AUTOSAR XML (schema 00047)
package /AUTOSAR/DiagnosticManagement/CompositionSwComponentTypes_Blueprint
  composition sw component type DM
    component DM1: type=DM1
package /AUTOSAR/DiagnosticManagement/AdaptiveApplicationSwComponentTypes_Blueprint
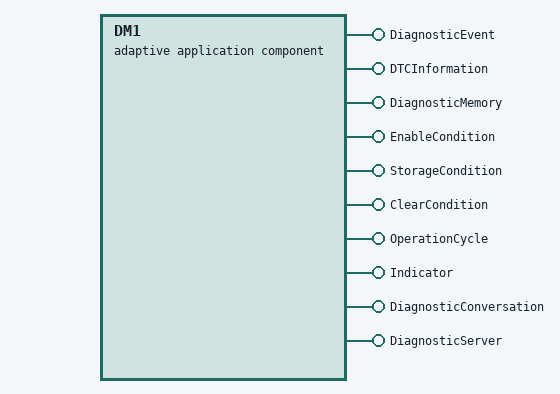
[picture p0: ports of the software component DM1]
  adaptive application sw component type DM1
    10 x provide port:
      DiagnosticEvent: variation-point=formal-blueprint-generator=expression=FOR SoftwareCluster : MODEL.filterType("SoftwareCluster"); DiagnosticEvent : MODEL.filterType("DiagnosticEvent"); WHERE DiagnosticEvent.isWithin(SoftwareCluster);, provided-interface=DiagnosticEvent  # Provides information on diagnostic event.
      DTCInformation: variation-point=formal-blueprint-generator=expression=FOR SoftwareCluster : MODEL.filterType("SoftwareCluster"); DiagnosticMemoryDestination : MODEL.filterType("DiagnosticMemoryDestination"); WHERE DiagnosticMemoryDestination.isWithin(SoftwareCluster);, provided-interface=DTCInformation  # Provides information on diagnostic event.
      DiagnosticMemory: variation-point=formal-blueprint-generator=expression=FOR SoftwareCluster : MODEL.filterType("SoftwareCluster"); DiagnosticMemoryDestination : MODEL.filterType("DiagnosticMemoryDestination"); WHERE DiagnosticMemoryDestination.isWithin(SoftwareCluster);, provided-interface=DiagnosticMemory  # Provides access to the fault memories.
      EnableCondition: variation-point=formal-blueprint-generator=expression=FOR SoftwareCluster : MODEL.filterType("SoftwareCluster"); DiagnosticEnableCondition : MODEL.filterType("DiagnosticEnableCondition"); WHERE DiagnosticEnableCondition.isWithin(SoftwareCluster);, provided-interface=EnableCondition  # Provides functionality for handling of enable conditions.
      StorageCondition: variation-point=formal-blueprint-generator=expression=FOR SoftwareCluster : MODEL.filterType("SoftwareCluster"); DiagnosticStorageCondition : MODEL.filterType("DiagnosticStorageCondition"); WHERE DiagnosticStorageCondition.isWithin(SoftwareCluster);, provided-interface=StorageCondition  # Provides functionality for handling of storage conditions.
      ClearCondition: variation-point=formal-blueprint-generator=expression=FOR SoftwareCluster : MODEL.filterType("SoftwareCluster"); DiagnosticClearCondition : MODEL.filterType("DiagnosticClearCondition"); WHERE DiagnosticClearCondition.isWithin(SoftwareCluster);, provided-interface=ClearCondition  # Provides functionality for handling of clear conditions.
      OperationCycle: variation-point=formal-blueprint-generator=expression=FOR SoftwareCluster : MODEL.filterType("SoftwareCluster"); DiagnosticOperationCycle : MODEL.filterType("DiagnosticOperationCycle"); WHERE DiagnosticOperationCycle.isWithin(SoftwareCluster);, provided-interface=OperationCycle  # Provides functionality for handling of operation cycles.
      Indicator: variation-point=formal-blueprint-generator=expression=FOR SoftwareCluster : MODEL.filterType("SoftwareCluster"); DiagnosticIndicator : MODEL.filterType("DiagnosticIndicator"); WHERE DiagnosticIndicator.isWithin(SoftwareCluster);, provided-interface=Indicator  # Provides functionality for handling of indicators.
      DiagnosticConversation: variation-point=formal-blueprint-generator=expression=FOR SoftwareCluster : MODEL.filterType("SoftwareCluster"); Number : MODEL.filterType("Number"); WHERE Number.isWithin(SoftwareCluster);, provided-interface=DiagnosticConversation  # Provides information about Diagnostic Conversation.
      DiagnosticServer: variation-point=formal-blueprint-generator=expression=FOR SoftwareCluster : MODEL.filterType("SoftwareCluster");, provided-interface=DiagnosticServer  # Provides information about the ControlDTCStatus
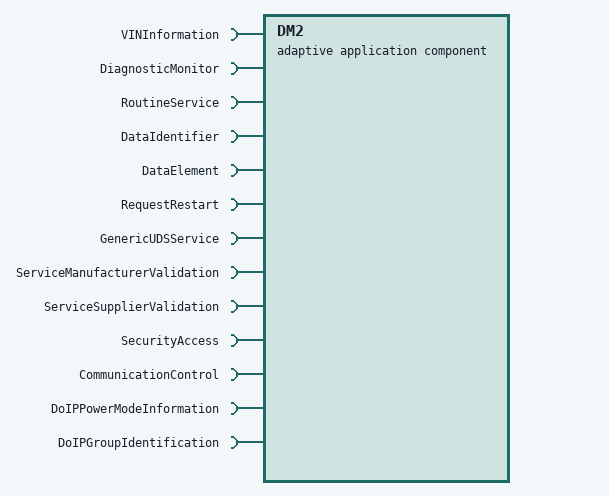
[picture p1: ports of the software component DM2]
  adaptive application sw component type DM2
    13 x require port:
      VINInformation: required-interface=VINInformation  # Requires handler for VIN information.
      DiagnosticMonitor: variation-point=formal-blueprint-generator=expression=FOR SoftwareCluster : MODEL.filterType("SoftwareCluster"); DiagnosticEvent : MODEL.filterType("DiagnosticEvent"); WHERE DiagnosticEvent.isWithin(SoftwareCluster);, required-interface=DiagnosticMonitor  # Requires diagnostic monitor reporting results of diagnostic event monitoring.
      RoutineService: variation-point=formal-blueprint-generator=expression=FOR SoftwareCluster : MODEL.filterType("SoftwareCluster"); DiagnosticRoutine : MODEL.filterType("DiagnosticRoutine"); WHERE DiagnosticRoutine.isWithin(SoftwareCluster);, required-interface=RoutineService  # Requires application providing methods of configured signature.
      DataIdentifier: variation-point=formal-blueprint-generator=expression=FOR SoftwareCluster : MODEL.filterType("SoftwareCluster"); DiagnosticDataIdentifier : MODEL.filterType("DiagnosticDataIdentifier"); WHERE DiagnosticDataIdentifier.isWithin(SoftwareCluster);, required-interface=DataIdentifier  # This is the default service interface for a DiagnosticDataIdentifier.
      DataElement: variation-point=formal-blueprint-generator=expression=FOR SoftwareCluster : MODEL.filterType("SoftwareCluster"); DiagnosticDataElement : MODEL.filterType("DiagnosticDataElement"); WHERE DiagnosticDataElement.isWithin(SoftwareCluster);, required-interface=DataElement  # This is the service interface for any DiagnosticDataElement which is not used within a DataIdentifier service.
      RequestRestart: variation-point=formal-blueprint-generator=expression=FOR SoftwareCluster : MODEL.filterType("SoftwareCluster");, required-interface=RequestRestart  # This is the service interface for requesting a restart of the machine, SWCL or application.
      GenericUDSService: variation-point=formal-blueprint-generator=expression=FOR SoftwareCluster : MODEL.filterType("SoftwareCluster"); DiagnosticServiceSwMapping : MODEL.filterType("DiagnosticServiceSwMapping"); WHERE DiagnosticServiceSwMapping.isWithin(SoftwareCluster);, required-interface=GenericUDSService  # Generic handler for UDS services. Can be mapped to any single diagnostic object (SID, Sub-Function, DID, RID,...).
      ServiceManufacturerValidation: variation-point=formal-blueprint-generator=expression=FOR SoftwareCluster : MODEL.filterType("SoftwareCluster");, required-interface=ServiceManufacturerValidation  # This service is the manufacturer notification handler.
      ServiceSupplierValidation: variation-point=formal-blueprint-generator=expression=FOR SoftwareCluster : MODEL.filterType("SoftwareCluster");, required-interface=ServiceSupplierValidation  # This service is the supplier notification handler.
      SecurityAccess: variation-point=formal-blueprint-generator=expression=FOR SoftwareCluster : MODEL.filterType("SoftwareCluster"); DiagnosticSecurityLevel : MODEL.filterType("DiagnosticSecurityLevel"); WHERE DiagnosticSecurityLevel.isWithin(SoftwareCluster);, required-interface=SecurityAccess  # SecurityAccess.
      CommunicationControl: variation-point=formal-blueprint-generator=expression=FOR SoftwareCluster : MODEL.filterType("SoftwareCluster");, required-interface=CommunicationControl  # CommunicationControl.
      DoIPPowerModeInformation: required-interface=DoIPPowerModeInformation
      DoIPGroupIdentification: required-interface=DoIPGroupIdentification
package /AUTOSAR/DiagnosticManagement/ServiceInterfaces_Blueprint
  23 x service interface, all with is-service=true:
    DiagnosticEvent
      namespaces:
        symbol props ara
        symbol props diag
      field EventStatus: type=EventStatusByteType, has-getter=true, has-notifier=true, has-setter=false  # Contains the current status of the event.
      field WIRStatus: type=WIRStatusType, has-getter=true, has-notifier=true, has-setter=true  # Contains the current WIR status of the event.
      methods:
        operation GetDTCNumber: possible-ap-error-set=Common  # Returns the DTC related to the event.
          arg DTCFormat: type=DTCFormatType, direction=IN, server-argument-impl-policy=USE-ARGUMENT-TYPE  # Define DTC format for the return value.
          arg DTCOfEvent: type=DTCType, direction=OUT, server-argument-impl-policy=USE-ARGUMENT-TYPE  # DTC number in respective DTCFormatType
        operation GetDebouncingStatus  # Gets the debouncing status of an event.
          arg debouncingState: type=DebouncingStateType, direction=OUT, server-argument-impl-policy=USE-ARGUMENT-TYPE  # Current debouncing state
        operation GetFaultDetectionCounter  # Returns the current value of fault detection counter of this event.
          arg faultDetectionCounter: type=FaultDetectionCounterType, direction=OUT, server-argument-impl-policy=USE-ARGUMENT-TYPE  # Current FaultDetectionCounter value
    DiagnosticMonitor
      namespaces:
        symbol props ara
        symbol props diag
      events:
        data MonitorAction: type=MonitorActionType  # Contains either the last (un-)qualified test result of the diagnostic monitor or commands to control the debouncing or to force a prestorage.
      methods:
        operation InitMonitor: fire-and-forget=true  # Event-specific notification for monitors about clearing, operation cycle restart or enable/storage condition re-enabling.
          arg reason: type=InitMonitorReasonType, direction=IN, server-argument-impl-policy=USE-ARGUMENT-TYPE  # The reason for initiallizing the monitor.
    DTCInformation
      namespaces:
        symbol props ara
        symbol props diag
      events:
        data DTCStatusChanged: type=DTCStatusChangedType  # Notification about the change in the status of a DTC.
        data SnapshotRecordUpdated: type=SnapshotRecordUpdatedType  # Notification about an update of a SnapshotRecord.
      methods:
        operation GetCurrentStatus: possible-ap-error-set=Common  # Determines the status of a DTC.
          arg DTC: type=DTCType, direction=IN, server-argument-impl-policy=USE-ARGUMENT-TYPE  # DTC whose status is requested.
          arg UdsDTCStatusByte: type=UdsDTCStatusByteType, direction=OUT, server-argument-impl-policy=USE-ARGUMENT-TYPE  # Contains the status of the DTC.
    DiagnosticMemory
      namespaces:
        symbol props ara
        symbol props diag
      field NumberOfStoredEntries: type=uint32_t, has-getter=true, has-notifier=true, has-setter=false  # Numbner of currently stored fault memory entries.
      methods:
        operation Clear: possible-ap-error-set=ClearFailedReason  # Method for Clearing a DTC or a group of DTCs.
          arg DTC: type=DTCGroupType, direction=IN, server-argument-impl-policy=USE-ARGUMENT-TYPE  # DTC group to be cleared.
    Indicator
      namespaces:
        symbol props ara
        symbol props diag
      field IndicatorStatus: type=IndicatorStatusType, has-getter=true, has-notifier=true, has-setter=false  # Contains the current state of an indicator.
    OperationCycle
      namespaces:
        symbol props ara
        symbol props diag
      field State: type=OperationCycleStateType, has-getter=true, has-notifier=true, has-setter=true  # Contains the current state of an operation cycle.
    StorageCondition
      namespaces:
        symbol props ara
        symbol props diag
      field State: type=StateType, has-getter=true, has-notifier=false, has-setter=true  # Contains the current state of an storage condition.
    EnableCondition
      namespaces:
        symbol props ara
        symbol props diag
      field State: type=StateType, has-getter=true, has-notifier=false, has-setter=true  # Contains the current state of an enable condition.
    ClearCondition
      namespaces:
        symbol props ara
        symbol props diag
      field State: type=StateType, has-getter=true, has-notifier=false, has-setter=true  # Contains the current state of an clear DTC condition.
    DiagnosticConversation
      namespaces:
        symbol props ara
        symbol props diag
      4 x field, all with has-getter=true, has-notifier=true, has-setter=false:
        ActivityStatus: type=ActivityStatusType  # Represents the status of an active conversation.
        DiagnosticSession: type=DiagnosticSessionType  # Represents the current active diagnostic session of an active conversation.
        DiagnosticSecurityLevel: type=DiagnosticSecurityLevelType  # Represents the current active diagnostic security level of an active conversation.
        Identifier: type=DiagnosticConversationIdentifierType  # Contains the identifier (i.e. DiagnosticProtocolKind, TargetAddress, SourceAddress) of the diagnostic conversation.
      methods:
        operation ResetToDefaultSession: fire-and-forget=true  # Method to reset the current session to default session.
    DiagnosticServer
      namespaces:
        symbol props ara
        symbol props diag
      field ControlDTCStatus: type=ControlDtcStatusType, has-getter=true, has-notifier=true, has-setter=false  # Contains the current status of the ControlDTCStatus
      methods:
        operation EnableControlDTC: fire-and-forget=true  # Enforce restoring DTC setting.
    RoutineService: variation-point=formal-blueprint-generator=expression=FOR SoftwareCluster : MODEL.filterType("SoftwareCluster"); DiagnosticRoutine : MODEL.filterType("DiagnosticRoutine"); WHERE DiagnosticRoutine.isWithin(SoftwareCluster);
      namespaces:
        symbol props ara
        symbol props diag
      methods:
        4 x operation:
          Start: possible-ap-error-set=UDSNegativeResponseCodeRegular, variation-point=blueprint-condition=note=p=l-1=Let Method Routine.getAttribute("start").  # Called for sub-function start of a routine.
            arg req_X:  # IN-Parameter of the start sub-function according to DiagnosticRoutine.
              type=custom
              direction=IN
              server-argument-impl-policy=USE-ARGUMENT-TYPE
              variation-point=formal-blueprint-generator={expression=FOR arg : Method.getAttribute("request"); LET DiagnosticDataElement = arg.getAttribute("dataElement"); swDataDefProps = DiagnosticDataElement.getAttribute("swDataDefProps"); BaseTypeRef = swDataDefProps.getAttribute("baseTypeRef");, "DataType according to {DiagnosticDataElement}.swDataDefProps."}
            arg metaInfo: type=MetaInfoType, direction=IN, server-argument-impl-policy=USE-ARGUMENT-TYPE  # MetaInfo of the request.
            arg resp_X:  # OUT-Parameter of the start sub-function according to DiagnosticRoutine.
              type=custom
              direction=OUT
              server-argument-impl-policy=USE-ARGUMENT-TYPE
              variation-point=formal-blueprint-generator={expression=FOR arg : Method.getAttribute("response"); LET DiagnosticDataElement = arg.getAttribute("dataElement"); swDataDefProps = DiagnosticDataElement.getAttribute("swDataDefProps"); BaseTypeRef = swDataDefProps.getAttribute("baseTypeRef");, "DataType according to {DiagnosticDataElement}.swDataDefProps."}
          Stop: possible-ap-error-set=UDSNegativeResponseCodeRegular, variation-point=blueprint-condition=note=p=l-1=Let Method Routine.getAttribute("stop").  # Called for sub-function stop of a routine if configured.
            arg req_X:  # IN-Parameter of the stop sub-function according to DiagnosticRoutine.
              type=custom
              direction=IN
              server-argument-impl-policy=USE-ARGUMENT-TYPE
              variation-point=formal-blueprint-generator={expression=FOR arg : Method.getAttribute("request"); LET DiagnosticDataElement = arg.getAttribute("dataElement"); swDataDefProps = DiagnosticDataElement.getAttribute("swDataDefProps"); BaseTypeRef = swDataDefProps.getAttribute("baseTypeRef");, "DataType according to {DiagnosticDataElement}.swDataDefProps."}
            arg metaInfo: type=MetaInfoType, direction=IN, server-argument-impl-policy=USE-ARGUMENT-TYPE  # MetaInfo of the request.
            arg resp_X:  # OUT-Parameter of the start sub-function according to DiagnosticRoutine.
              type=custom
              direction=OUT
              server-argument-impl-policy=USE-ARGUMENT-TYPE
              variation-point=formal-blueprint-generator={expression=FOR arg : Method.getAttribute("response"); LET DiagnosticDataElement = arg.getAttribute("dataElement"); swDataDefProps = DiagnosticDataElement.getAttribute("swDataDefProps"); BaseTypeRef = swDataDefProps.getAttribute("baseTypeRef");, "DataType according to {DiagnosticDataElement}.swDataDefProps."}
          RequestResults: possible-ap-error-set=UDSNegativeResponseCodeRegular, variation-point=blueprint-condition=note=p=l-1=Let Method Routine.getAttribute("requestResults").  # Called for sub-function requestRoutineResults of a routine if configured.
            arg req_X:  # IN-Parameter of the requestResults sub-function according to DiagnosticRoutine.
              type=custom
              direction=IN
              server-argument-impl-policy=USE-ARGUMENT-TYPE
              variation-point=formal-blueprint-generator={expression=FOR arg : Method.getAttribute("request"); LET DiagnosticDataElement = arg.getAttribute("dataElement"); swDataDefProps = DiagnosticDataElement.getAttribute("swDataDefProps"); BaseTypeRef = swDataDefProps.getAttribute("baseTypeRef");, "DataType according to {DiagnosticDataElement}.swDataDefProps."}
            arg metaInfo: type=MetaInfoType, direction=IN, server-argument-impl-policy=USE-ARGUMENT-TYPE  # MetaInfo of the request.
            arg resp_X:  # OUT-Parameter of the requestRoutineResults sub-function according to DiagnosticRoutine.
              type=custom
              direction=OUT
              server-argument-impl-policy=USE-ARGUMENT-TYPE
              variation-point=formal-blueprint-generator={expression=FOR arg : Method.getAttribute("response"); LET DiagnosticDataElement = arg.getAttribute("dataElement"); swDataDefProps = DiagnosticDataElement.getAttribute("swDataDefProps"); BaseTypeRef = swDataDefProps.getAttribute("baseTypeRef");, "DataType according to {DiagnosticDataElement}.swDataDefProps."}
          Cancel: fire-and-forget=true  # Called if the current conversation is canceled.
            arg metaInfo: type=MetaInfoType, direction=IN, server-argument-impl-policy=USE-ARGUMENT-TYPE, variation-point=blueprint-condition=note=p=l-1=MetaInfoType: Meta-Inf map, which contains key-value pairs according to MetaInfoKeyType.  # MetaInfo of the request.
    DataIdentifier: variation-point=formal-blueprint-generator=expression=FOR SoftwareCluster : MODEL.filterType("SoftwareCluster"); DiagnosticDataIdentifier : MODEL.filterType("DiagnosticDataIdentifier"); WHERE DiagnosticDataIdentifier.isWithin(SoftwareCluster);
      namespaces:
        symbol props ara
        symbol props diag
      methods:
        operation Read: possible-ap-error-set=UDSNegativeResponseCodeRegular  # Called for ReadDataByIdentifer request for this DiagnosticDataIdentifier (if configured).
          arg metaInfo: type=MetaInfoType, direction=IN, server-argument-impl-policy=USE-ARGUMENT-TYPE  # MetaInfo of the request.
          arg dataRecord:  # DataElement within response message.
            type=custom
            direction=OUT
            server-argument-impl-policy=USE-ARGUMENT-TYPE
            variation-point=formal-blueprint-generator={expression=FOR arg : Method.getAttribute("dataElement"); LET DiagnosticDataElement = arg.getAttribute("dataElement"); swDataDefProps = DiagnosticDataElement.getAttribute("swDataDefProps"); BaseTypeRef = swDataDefProps.getAttribute("baseTypeRef");, "DataType according to {DiagnosticDataElement}.swDataDefProps."}
        operation Write: possible-ap-error-set=UDSNegativeResponseCodeRegular  # Called for WriteDataByIdentifer request for this DiagnosticDataIdentifier (if configured).
          arg metaInfo: type=MetaInfoType, direction=IN, server-argument-impl-policy=USE-ARGUMENT-TYPE, variation-point=blueprint-condition=note=p=l-1=MetaInfoType: Meta-Inf map, which contains key-value pairs according to MetaInfoKeyType.  # MetaInfo of the request.
          arg dataRecord:  # DataElement within the request message.
            type=custom
            direction=IN
            server-argument-impl-policy=USE-ARGUMENT-TYPE
            variation-point=formal-blueprint-generator={expression=FOR arg : Method.getAttribute("dataElement"); LET DiagnosticDataElement = arg.getAttribute("dataElement"); swDataDefProps = DiagnosticDataElement.getAttribute("swDataDefProps"); BaseTypeRef = swDataDefProps.getAttribute("baseTypeRef");, "DataType according to {DiagnosticDataElement}.swDataDefProps."}
        operation Cancel: fire-and-forget=true  # Called if the current conversation is canceled.
          arg metaInfo: type=MetaInfoType, direction=IN, server-argument-impl-policy=USE-ARGUMENT-TYPE, variation-point=blueprint-condition=note=p=l-1=MetaInfoType: Meta-Inf map, which contains key-value pairs according to MetaInfoKeyType.  # MetaInfo of the request.
    DataElement: variation-point=formal-blueprint-generator=expression=FOR SoftwareCluster : MODEL.filterType("SoftwareCluster"); DiagnosticDataElement : MODEL.filterType("DiagnosticDataElement"); WHERE DiagnosticDataElement.isWithin(SoftwareCluster);
      namespaces:
        symbol props ara
        symbol props diag
        symbol props DataElement
      methods:
        operation Read: possible-ap-error-set=UDSNegativeResponseCodeRegular  # Called for data aquisition of a DiagnosticDataElement.
          arg metaInfo: type=MetaInfoType, direction=IN, server-argument-impl-policy=USE-ARGUMENT-TYPE  # MetaInfo of the request.
          arg dataRecord: type=custom, direction=OUT, server-argument-impl-policy=USE-ARGUMENT-TYPE, variation-point=blueprint-condition=note=p=l-1=DataType according to {DiagnosticDataElement}.swDataDefProps.  # OUT-Parameter.
        operation Cancel: fire-and-forget=true  # Called if the current conversation is canceled.
          arg metaInfo: type=MetaInfoType, direction=IN, server-argument-impl-policy=USE-ARGUMENT-TYPE, variation-point=blueprint-condition=note=p=l-1=MetaInfoType: Meta-Inf map, which contains key-value pairs according to MetaInfoKeyType.  # MetaInfo of the request.
    RequestRestart
      namespaces:
        symbol props ara
        symbol props diag
      methods:
        operation RequestRestart: possible-ap-error-set=RequestRestart  # Requests a restart of SoftwareCluster(s) or parts of SoftwareCluster(s) running on the machine.
          arg RestartType: type=RestartTypeType, direction=IN, server-argument-impl-policy=USE-ARGUMENT-TYPE  # Type of the requested reset.
          arg ExecutionType: type=ExecutionTypeType, direction=IN, server-argument-impl-policy=USE-ARGUMENT-TYPE  # Type of execution: Immediate is synchronous (i.e. restart has happend when this method return); Defered is asynchronous (i.e. restart is defered to later point in time)
    GenericUDSService
      namespaces:
        symbol props ara
        symbol props diag
      methods:
        operation HandleMessage: possible-ap-error-set=UDSNegativeResponseCodeRegular  # Called for any request messsage of the mapped DiagnosticServiceSwMapping.
          4 x arg, all with server-argument-impl-policy=USE-ARGUMENT-TYPE:
            SID: type=SIDType, direction=IN  # Diagnostic Request Service Identifier.
            requestData: type=ByteVectorType, direction=IN  # Diagnostic request data (starting after SID).
            metaInfo: type=MetaInfoType, direction=IN, variation-point=blueprint-condition=note=p=l-1=MetaInfoType: Meta-Inf map, which contains key-value pairs according to MetaInfoKeyType.  # MetaInfo of the request.
            responseData: type=ByteVectorType, direction=OUT  # Diagnostic response data (starting after SID).
        operation Cancel: fire-and-forget=true  # Called if the current conversation is canceled.
          arg metaInfo: type=MetaInfoType, direction=IN, server-argument-impl-policy=USE-ARGUMENT-TYPE, variation-point=blueprint-condition=note=p=l-1=MetaInfoType: Meta-Inf map, which contains key-value pairs according to MetaInfoKeyType.  # MetaInfo of the request.
    ServiceManufacturerValidation
      namespaces:
        symbol props ara
        symbol props diag
      methods:
        operation Validate: possible-ap-error-set=UDSNegativeResponseCodeValidation  # Called for any request message.
          arg requestData: type=ByteVectorType, direction=IN, server-argument-impl-policy=USE-ARGUMENT-TYPE  # Diagnostic request message including SID.
          arg metaInfo: type=MetaInfoType, direction=IN, server-argument-impl-policy=USE-ARGUMENT-TYPE, variation-point=blueprint-condition=note=p=l-1=MetaInfoType: Meta-Inf map, which contains key-value pairs according to MetaInfoKeyType.  # MetaInfo of the request.
        operation Confirmation: fire-and-forget=true  # This method is called by DM on a configured manufacturer/supplier notification handler, when a diagnostic request has been finished, to notify the handler about the outcome.
          arg status: type=ConfirmationStatusType, direction=IN, server-argument-impl-policy=USE-ARGUMENT-TYPE  # status/outcome of the service processing.
          arg metaInfo: type=MetaInfoType, direction=IN, server-argument-impl-policy=USE-ARGUMENT-TYPE, variation-point=blueprint-condition=note=p=l-1=MetaInfoType: Meta-Inf map, which contains key-value pairs according to MetaInfoKeyType.  # MetaInfo of the request.
    ServiceSupplierValidation
      namespaces:
        symbol props ara
        symbol props diag
      methods:
        operation Validate: possible-ap-error-set=UDSNegativeResponseCodeValidation  # Called for any request message.
          arg requestData: type=ByteVectorType, direction=IN, server-argument-impl-policy=USE-ARGUMENT-TYPE  # Diagnostic request message including SID.
          arg metaInfo: type=MetaInfoType, direction=IN, server-argument-impl-policy=USE-ARGUMENT-TYPE, variation-point=blueprint-condition=note=p=l-1=MetaInfoType: Meta-Inf map, which contains key-value pairs according to MetaInfoKeyType.  # MetaInfo of the request.
        operation Confirmation: fire-and-forget=true  # This method is called by DM on a configured manufacturer/supplier notification handler, when a diagnostic request has been finished, to notify the handler about the outcome.
          arg status: type=ConfirmationStatusType, direction=IN, server-argument-impl-policy=USE-ARGUMENT-TYPE  # status/outcome of the service processing.
          arg metaInfo: type=MetaInfoType, direction=IN, server-argument-impl-policy=USE-ARGUMENT-TYPE, variation-point=blueprint-condition=note=p=l-1=MetaInfoType: Meta-Inf map, which contains key-value pairs according to MetaInfoKeyType.  # MetaInfo of the request.
    CommunicationControl
      namespaces:
        symbol props ara
        symbol props diag
      methods:
        operation CommCtrlRequest: possible-ap-error-set=UDSNegativeResponseCodeRegular  # Called for CommunicationControl (x028) with any subfunction as subfunction value is part of argument list. Typically provider of this interface is considered as part of the state management.
          arg requestParams: type=ComCtrlRequestParamsType, direction=IN, server-argument-impl-policy=USE-ARGUMENT-TYPE  # All UDS request parameters packed into a structure since it holds optional elementr
          arg metaInfo: type=MetaInfoType, direction=IN, server-argument-impl-policy=USE-ARGUMENT-TYPE, variation-point=blueprint-condition=note=p=l-1=MetaInfoType: Meta-Inf map, which contains key-value pairs according to MetaInfoKeyType.  # MetaInfo of the request.
    SecurityAccess
      namespaces:
        symbol props ara
        symbol props diag
      methods:
        operation GetSeed: possible-ap-error-set=UDSNegativeResponseCodeRegular  # Called for SecurityAccess (x027) with subfunction requestSeedId if configured (see DiagnosticSecurityAccess)
          arg securityAccessDataRecord: type=ByteVectorType, direction=IN, server-argument-impl-policy=USE-ARGUMENT-TYPE  # provided securityAccessDataRecord
          arg metaInfo: type=MetaInfoType, direction=IN, server-argument-impl-policy=USE-ARGUMENT-TYPE, variation-point=blueprint-condition=note=p=l-1=MetaInfoType: Meta-Inf map, which contains key-value pairs according to MetaInfoKeyType.  # MetaInfo of the request.
          arg seed: type=ByteVectorType, direction=OUT, server-argument-impl-policy=USE-ARGUMENT-TYPE  # provided seed
        operation CompareKey: possible-ap-error-set=UDSNegativeResponseCodeRegular  # Called for SecurityAccess (x027) with subfunction sendKey if configured (see DiagnosticSecurityAccess).
          arg key: type=ByteVectorType, direction=IN, server-argument-impl-policy=USE-ARGUMENT-TYPE  # The key to be validated
          arg metaInfo: type=MetaInfoType, direction=IN, server-argument-impl-policy=USE-ARGUMENT-TYPE, variation-point=blueprint-condition=note=p=l-1=MetaInfoType: Meta-Inf map, which contains key-value pairs according to MetaInfoKeyType.  # MetaInfo of the request.
          arg result: type=KeyCompareResultType, direction=OUT, server-argument-impl-policy=USE-ARGUMENT-TYPE  # Result of the key validation.
        operation Cancel: fire-and-forget=true  # Called if the current conversation is canceled.
          arg metaInfo: type=MetaInfoType, direction=IN, server-argument-impl-policy=USE-ARGUMENT-TYPE, variation-point=blueprint-condition=note=p=l-1=MetaInfoType: Meta-Inf map, which contains key-value pairs according to MetaInfoKeyType.  # MetaInfo of the request.
    DoIPPowerModeInformation
      namespaces:
        symbol props ara
        symbol props diag
      field PowerMode: type=uint8_t, has-getter=true, has-notifier=true, has-setter=false  # Contains the current power state for the DoIP protocol.
    DoIPGroupIdentification
      namespaces:
        symbol props ara
        symbol props diag
      field GIDstatus: type=GIDstatusType, has-getter=true, has-notifier=true, has-setter=false  # Contains the current GID state for the DoIP protocol.
    VINInformation
      namespaces:
        symbol props ara
        symbol props diag
      methods:
        operation Read: possible-ap-error-set=UDSNegativeResponseCodeRegular  # Called for reading the VIN.
          arg metaInfo: type=MetaInfoType, direction=IN, server-argument-impl-policy=USE-ARGUMENT-TYPE, variation-point=blueprint-condition=note=p=l-1=MetaInfoType: Meta-Inf map, which contains key-value pairs according to MetaInfoKeyType.  # MetaInfo of the request.
          arg vin: type=VINType, direction=OUT  # VIN data.
        operation Write: possible-ap-error-set=UDSNegativeResponseCodeRegular  # Called for writing the VIN.
          arg vin: type=VINType, direction=IN  # VIN data.
          arg metaInfo: type=MetaInfoType, direction=IN, server-argument-impl-policy=USE-ARGUMENT-TYPE, variation-point=blueprint-condition=note=p=l-1=MetaInfoType: Meta-Inf map, which contains key-value pairs according to MetaInfoKeyType.  # MetaInfo of the request.
        operation Cancel: fire-and-forget=true  # Called if the current operation is canceled.
          arg metaInfo: type=MetaInfoType, direction=IN, server-argument-impl-policy=USE-ARGUMENT-TYPE, variation-point=blueprint-condition=note=p=l-1=MetaInfoType: Meta-Inf map, which contains key-value pairs according to MetaInfoKeyType.  # MetaInfo of the request.
package /AUTOSAR/ImplementationDataTypes_Blueprint
  37 x std cpp implementation data type:
    MonitorActionType:  # Represents the status information reported by AAs being relevant for error monitoring.
      compu {0x00=kPassed (Monitor reports qualified test result passed.), 0x01=kFailed (Monitor reports qualified test result failed), 0x02=kPrepassed (Monitor reports unqualified test result pre-passed.), 0x03=kPrefailed (Monitor reports unqualified test result pre-failed.), 0x04=kFdcThresholdReached (Monitor triggers the storage of ExtendedDataRecords and FreezeFrames (if the triggering condition is connected to this threshold).), 0x05=kResetTestFailed (Reset TestFailed Bit without any other side effects like readiness), 0x06=kFreezeDebouncing (Freeze the internal debounce counter/timer.), 0x07=kResetDebouncing (Reset the internal debounce counter/timer.), 0x08=kPrestore (Capture and prestores the freeze frame data.), 0x09=kClearPrestore (Clears a prestored freeze frame.)}
      range raw 0x00..0x09
      type-reference=uint8_t
      namespaces:
        symbol props ara
        symbol props diag
    SIDType: type-reference=uint8_t
      namespaces:
        symbol props ara
        symbol props diag
    InitMonitorReasonType: compu {0x00=kClear (Event was cleared and all internal values and states are reset.), 0x01=kRestart (Operation cycle of the event was (re-)started), 0x02=kReenabled (Enable conditions or DTC settings re-enabled.), 0x03=kStorageReenabled (Storage condition reenabled.)}, range raw 0x01..0x04, type-reference=uint8_t
      namespaces:
        symbol props ara
        symbol props diag
    EventStatusByteType:
      compu {mask 0x01: 0=FALSE (kTestFailed) (bit 0: TestFailed), mask 0x01: 1=TRUE (kTestFailed) (bit 0: TestFailed), mask 0x02: 0=FALSE (kTestFailedThisOperationCycle) (bit 1: TestFailedThisOperationCycle), mask 0x02: 2=TRUE (kTestFailedThisOperationCycle) (bit 1: TestFailedThisOperationCycle), mask 0x40: 0=FALSE (kTestNotCompletedThisOperationCycle) (bit 6: TestNotCompletedThisOperationCycle), mask 0x40: 64=TRUE (kTestNotCompletedThisOperationCycle) (bit 6: TestNotCompletedThisOperationCycle)}
      range raw 0x00..0xFF
      type-reference=uint8_t
      namespaces:
        symbol props ara
        symbol props diag
    DTCFormatType: compu {0=kDTCFormatOBD, 1=kDTCFormatUDS, 2=kDTCFormatJ1939}, range raw 0..2, type-reference=uint8_t
      namespaces:
        symbol props ara
        symbol props diag
    DebouncingStateType:
      compu {mask 0x01: 0=FALSE (kTemporarilyDefective) (Bit 0: Temporarily Defective (corresponds to 0 < FDC < 127)), mask 0x01: 1=TRUE (kTemporarilyDefective) (Bit 0: Temporarily Defective (corresponds to 0 < FDC < 127)), mask 0x02: 0=FALSE (kFinallyDefective) (Bit 1: finally Defective (corresponds to FDC = 127)), mask 0x02: 2=TRUE (kFinallyDefective) (Bit 1: finally Defective (corresponds to FDC = 127)), mask 0x04: 0=FALSE (kTemporarilyHealed) (Bit 2: temporarily healed (corresponds to -128 < FDC < 0)), mask 0x04: 4=TRUE (kTemporarilyHealed) (Bit 2: temporarily healed (corresponds to -128 < FDC < 0)), mask 0x08: 0=FALSE (kTestComplete) (Bit 3: Test complete (corresponds to FDC = -128 or FDC = 127)), mask 0x08: 8=TRUE (kTestComplete) (Bit 3: Test complete (corresponds to FDC = -128 or FDC = 127)), mask 0x10: 0=FALSE (kDTRUpdate) (Bit 4: DTR Update (= Test complete && Debouncing complete && enable conditions / storage conditions fulfilled)), mask 0x10: 16=TRUE (kDTRUpdate) (Bit 4: DTR Update (= Test complete && Debouncing complete && enable conditions / storage conditions fulfilled))}
      range raw 0x00..0x1F
      type-reference=uint8_t
      namespaces:
        symbol props ara
        symbol props diag
    FaultDetectionCounterType: type-reference=uint8_t  # sint8
      namespaces:
        symbol props ara
        symbol props diag
    MetaInfoType: category=ASSOCIATIVE_MAP, template-arguments=[string, string]  # Meta-Inf map, which contains key-value pairs of MetaInfoKeyType, MetaInfoValueType.
    ComCtrlRequestParamsType: category=STRUCTURE  # ComCtrlRequestParamsType is a structure, which holds all parameters of an UDS 0x28 communicationControl request.
      cpp implementation data type element controlType: type-reference={inplace=false, type-reference=uint8_t}  # controlType parameter controls enabling/disabling of Rx/Tx capabilities also optionally for sub-busses.
      cpp implementation data type element communicationType: type-reference={inplace=false, type-reference=uint8_t}  # communicationType parameter controls which kind of communication messages are impacted.
      cpp implementation data type element nodeIdentificationNumber: is-optional=true, type-reference={inplace=false, type-reference=uint16_t}  # nodeIdentificationNumber defines a network node impacted by the request, which shall be controlled by a master receiving the request. Only valid in case controlType is set to 0x04 or 0x05.
    DTCStatusChangedType: category=STRUCTURE
      cpp implementation data type element DTC: type-reference={inplace=false, type-reference=DTCType}
      cpp implementation data type element udsDTCStatusByteOld: type-reference={inplace=false, type-reference=UdsDTCStatusByteType}
      cpp implementation data type element udsDTCStatusByteNew: type-reference={inplace=false, type-reference=UdsDTCStatusByteType}
    SnapshotRecordUpdatedType: category=STRUCTURE  # Contains the content of the updated snapshot record and the corresponding DTC number.
      cpp implementation data type element DTC: type-reference={inplace=false, type-reference=DTCType}
      cpp implementation data type element snapshotDataRecord: type-reference={inplace=false, type-reference=SnapshotDataRecordsType}
    SnapshotDataRecordsType: category=VECTOR, cpp-template-argument=SnapshotDataRecordType
    SnapshotDataRecordType: category=STRUCTURE  # Type containing a snapshot record number and its data of the snapshot record
      cpp implementation data type element snapshotRecordNumber: type-reference={inplace=false, type-reference=uint8_t}
      cpp implementation data type element snapshotDataIdentifers: type-reference={inplace=false, type-reference=SnapshotDataIdentifersType}
    SnapshotDataIdentifersType: category=VECTOR, cpp-template-argument=SnapshotDataIdentiferType
    SnapshotDataIdentiferType: category=STRUCTURE  # Type containing a DID number and its data.
      cpp implementation data type element dataIdentifer: type-reference={inplace=false, type-reference=uint16_t}
      cpp implementation data type element dataElements: type-reference={inplace=false, type-reference=ByteVectorType}
    DTCType: type-reference=uint32_t  # uint32
      namespaces:
        symbol props ara
        symbol props diag
    WIRStatusType: type-reference=bool  # bool
      namespaces:
        symbol props ara
        symbol props diag
    DTCGroupType: type-reference=uint32_t  # uint32
      namespaces:
        symbol props ara
        symbol props diag
    UdsDTCStatusByteType:
      compu {mask 0x01: 0=FALSE (kTestFailed) (bit 0: TestFailed), mask 0x01: 1=TRUE (kTestFailed) (bit 0: TestFailed), mask 0x02: 0=FALSE (kTestFailedThisOperationCycle) (bit 1: TestFailedThisOperationCycle), mask 0x02: 2=TRUE (kTestFailedThisOperationCycle) (bit 1: TestFailedThisOperationCycle), mask 0x04: 0=FALSE (kPendingDTC) (bit 2: PendingDTC), mask 0x04: 4=TRUE (kPendingDTC) (bit 2: PendingDTC), mask 0x08: 0=FALSE (kConfirmedDTC) (bit 3: ConfirmedDTC), mask 0x08: 8=TRUE (kConfirmedDTC) (bit 3: ConfirmedDTC), mask 0x10: 0=FALSE (kTestNotCompletedSinceLastClear) (bit 4: TestNotCompletedSinceLastClear), mask 0x10: 16=TRUE (kTestNotCompletedSinceLastClear) (bit 4: TestNotCompletedSinceLastClear), mask 0x20: 0=FALSE (kTestFailedSinceLastClear) (bit 5: TestFailedSinceLastClear), mask 0x20: 32=TRUE (kTestFailedSinceLastClear) (bit 5: TestFailedSinceLastClear), mask 0x40: 0=FALSE (kTestNotCompletedThisOperationCycle) (bit 6: TestNotCompletedThisOperationCycle), mask 0x40: 64=TRUE (kTestNotCompletedThisOperationCycle) (bit 6: TestNotCompletedThisOperationCycle), mask 0x80: 0=FALSE (kWarningIndicatorRequested) (bit 7: WarningIndicatorRequested), mask 0x80: 128=TRUE (kWarningIndicatorRequested) (bit 7: WarningIndicatorRequested)}
      range raw 0x00..0xFF
      type-reference=uint8_t
      namespaces:
        symbol props ara
        symbol props diag
    StateType: type-reference=bool  # boolean
      namespaces:
        symbol props ara
        symbol props diag
    IndicatorStatusType:
      compu {0x00=kOff (Indicator off mode), 0x01=kContinous (Indicator continuously on mode), 0x02=kBlinking (Indicator blinking mode), 0x03=kBlinkingAndContinous (Indicator blinking or continuously on mode), 0x04=kSlowFlash (Indicator slow flashing mode), 0x05=kFastFlash (Indicator fast flashing mode), 0x06=kOnDemand (Indicator on-demand mode), 0x07=kShort (Indicator short mode)}
      range raw 0x00..0x07
      type-reference=uint8_t
      namespaces:
        symbol props ara
        symbol props diag
    OperationCycleStateType: compu {0x00=kStart (Start/restart the operation cycle.), 0x01=kEnd (End the operation cycle)}, range raw 0x00..0x01, type-reference=uint8_t  # Represents the state information of operation cycles.
      namespaces:
        symbol props ara
        symbol props diag
    DiagnosticSessionType: type-reference=string  # Represents the Diagnostic Session.
      namespaces:
        symbol props ara
        symbol props diag
    RestartTypeType: type-reference=string  # Represents the type of restart/reset.
      namespaces:
        symbol props ara
        symbol props diag
    DiagnosticSecurityLevelType: type-reference=string  # Represents the Diagnostic Security Level.
      namespaces:
        symbol props ara
        symbol props diag
    DiagnosticConversationIdentifierType: category=STRUCTURE  # Characterizes an ongoing Diagnostic Conversation.
      cpp implementation data type element diagnosticProtocolKind: type-reference={inplace=false, type-reference=string}
      cpp implementation data type element diagnsoticServerAddress: type-reference={inplace=false, type-reference=UdsAddressType}
      cpp implementation data type element testerAddress: type-reference={inplace=false, type-reference=UdsAddressType}
    ByteVectorType: category=VECTOR, cpp-template-argument=uint8_t  # DataArrayType
    UdsAddressType: type-reference=uint16_t  # Represents the UDS Address as defined in ISO-14229-1.
      namespaces:
        symbol props ara
        symbol props diag
    ActivityStatusType: compu {0x00=kActive (Currently active; i.e. request is curretnly processed or non-default session is active.), 0x01=kInactive (Currently not active)}, range raw 0x00..0x01, type-reference=uint8_t  # Possible states of an diagnostic conversation.
      namespaces:
        symbol props ara
        symbol props diag
    ExecutionTypeType: compu {0x00=kImmediate (synchronous execution of restart (i.e. restart has happend when this method return).), 0x01=kDefered (asynchronous execution of restart (i.e. restart is defered to later point in time))}, range raw 0x00..0x01, type-reference=uint8_t  # Type of execution of the restart.
      namespaces:
        symbol props ara
        symbol props diag
    ConfirmationStatusType:  # Type used in the method confirmed for the status of the service processing
      compu {0x00=kResPosOk (Positive response has been sent out successfully), 0x01=kResPosNotOk (Positive response has not been sent out successfully), 0x02=kResNegOk (Negative response has been sent out successfull), 0x03=kResNegNotOk (Negative response has not been sent out successfully), 0x04=kResPosSuppressed (Positive answer suppressed), 0x05=kResNegSuppressed (Negative answer suppressed), 0x06=kCanceled (Processing is canceled), 0x07=kNoProcessingNoResponse (Processing rejected in Validation)}
      range raw 0x00..0x04
      type-reference=uint8_t
      namespaces:
        symbol props ara
        symbol props diag
    ControlDtcStatusType: compu {0x00=kDTCSettingOn (Updating of diagnostic trouble code status bits is under normal operating conditions), 0x01=kDTCSettingOff (Updating of diagnostic trouble code status bits is stopped)}, range raw 0x00..0x02, type-reference=uint8_t  # Type for ControlDTCStatus status
      namespaces:
        symbol props ara
        symbol props diag
    KeyCompareResultType: compu {0x00=kKeyValid (Key is valid), 0x01=kKeyInvalid (Key is invalid)}, range raw 0x00..0x02, type-reference=uint8_t
      namespaces:
        symbol props ara
        symbol props diag
    GIDstatusType: category=STRUCTURE  # Type used in the method confirmed for the status of the service processing
      cpp implementation data type element GID: type-reference={inplace=false, type-reference=GIDType}
      cpp implementation data type element furtherActionReq: type-reference={inplace=false, type-reference=uint8_t}
      cpp implementation data type element syncStatus: type-reference={inplace=false, type-reference=uint8_t}
    GIDType: category=ARRAY, array-size=6, cpp-template-argument=uint8_t  # 6 byte array of uint8 representing the GID
    VINType: category=ARRAY, array-size=17, cpp-template-argument=uint8_t  # 17 byte array of uint8 representing the VIN
    custom
package /AUTOSAR/ApApplicationErrors_Blueprint
  ap application error domain Diag_Common
  ap application error kNoSuchDTC: error-code=0, error-domain=Diag_Common  # No DTC available.
  ap application error set Common: ap-application-error=kNoSuchDTC  # This error set include the error to reject the restart execution.
  ap application error domain Diag_RequestRestart
  ap application error kRejected: error-code=0, error-domain=Diag_RequestRestart  # Reject the request to restart.
  ap application error set RequestRestart: ap-application-error=kRejected  # This error set include the error to reject the restart execution.
  ap application error domain Diag_ClearFailedReason
  4 x ap application error, all with error-domain=Diag_ClearFailedReason:
    kFailed: error-code=0  # Failed to clear the DTC due to any other reason.
    kBusy: error-code=1  # DTC not cleared, as another clearing process is in progress. The caller can retry later.
    kMemoryError: error-code=2  # An error occurred during erasing a memory location.
    kWrongDtc: error-code=3  # DTC value does not exist in the current configuration
  ap application error set ClearFailedReason: ap-application-error=[kBusy, kFailed, kMemoryError, kWrongDtc]  # This error set includes the different kind of rejections to clear DTCs.
  ap application error domain Diag_UDSNegativeResponseCode
  40 x ap application error, all with error-domain=Diag_UDSNegativeResponseCode:
    kGeneralReject: error-code=0x10  # According to ISO.
    kServiceNotSupported: error-code=0x11  # According to ISO.
    kSubfunctionNotSupported: error-code=0x12  # According to ISO.
    kIncorrectMessageLengthOrInvalidFormat: error-code=0x13  # According to ISO.
    kResponseTooLong: error-code=0x14  # According to ISO.
    kBusyRepeatRequest: error-code=0x21  # According to ISO.
    kConditionsNotCorrect: error-code=0x22  # According to ISO.
    kRequestSequenceError: error-code=0x24  # According to ISO.
    kNoResponseFromSubnetComponent: error-code=0x25  # According to ISO.
    kFailurePreventsExecutionOfRequestedAction: error-code=0x26  # According to ISO.
    kRequestOutOfRange: error-code=0x31  # According to ISO.
    kSecurityAccessDenied: error-code=0x33  # According to ISO.
    kInvalidKey: error-code=0x35  # According to ISO.
    kExceedNumberOfAttempts: error-code=0x36  # According to ISO.
    kRequiredTimeDelayNotExpired: error-code=0x37  # According to ISO.
    kUploadDownloadNotAccepted: error-code=0x70  # According to ISO.
    kTransferDataSuspended: error-code=0x71  # According to ISO.
    kGeneralProgrammingFailure: error-code=0x72  # According to ISO.
    kWrongBlockSequenceCounter: error-code=0x73  # According to ISO.
    kSubFunctionNotSupportedInActiveSession: error-code=0x7E  # According to ISO.
    kServiceNotSupportedInActiveSession: error-code=0x7F  # According to ISO.
    kRpmTooHigh: error-code=0x81  # According to ISO.
    kRpmTooLow: error-code=0x82  # According to ISO.
    kEngineIsRunning: error-code=0x83  # According to ISO.
    kEngineIsNotRunning: error-code=0x84  # According to ISO.
    kEngineRunTimeTooLow: error-code=0x85  # According to ISO.
    kTemperatureTooHigh: error-code=0x86  # According to ISO.
    kTemperatureTooLow: error-code=0x87  # According to ISO.
    kVehicleSpeedTooHigh: error-code=0x88  # According to ISO.
    kVehicleSpeedTooLow: error-code=0x89  # According to ISO.
    kThrottlePedalTooHigh: error-code=0x8A  # According to ISO.
    kThrottlePedalTooLow: error-code=0x8B  # According to ISO.
    kTransmissionRangeNotInNeutral: error-code=0x8C  # According to ISO.
    kTransmissionRangeNotInGear: error-code=0x8D  # According to ISO.
    kBrakeSwitchNotClosed: error-code=0x8F  # According to ISO.
    kShifterLeverNotInPark: error-code=0x90  # According to ISO.
    kTorqueConverterClutchLocked: error-code=0x91  # According to ISO.
    kVoltageTooHigh: error-code=0x92  # According to ISO.
    kVoltageTooLow: error-code=0x93  # According to ISO.
    kNoProcessingNoResponse: error-code=0xFF  # Deviating from ISO - no further service processing and no response (silently ignore request message).
  ap application error set UDSNegativeResponseCodeRegular: ap-application-error=[kBrakeSwitchNotClosed, kBusyRepeatRequest, kConditionsNotCorrect, kEngineIsNotRunning, kEngineIsRunning, kEngineRunTimeTooLow, kExceedNumberOfAttempts, kFailurePreventsExecutionOfRequestedAction, kGeneralReject, kGeneralProgrammingFailure, kIncorrectMessageLengthOrInvalidFormat, kInvalidKey, kNoResponseFromSubnetComponent, kResponseTooLong, kRequestOutOfRange, kRequestSequenceError, kRequiredTimeDelayNotExpired, kRpmTooHigh, kRpmTooLow, kSecurityAccessDenied, kServiceNotSupported, kServiceNotSupportedInActiveSession, kShifterLeverNotInPark, kSubfunctionNotSupported, kSubFunctionNotSupportedInActiveSession, kTemperatureTooHigh, kTemperatureTooLow, kTorqueConverterClutchLocked, kThrottlePedalTooHigh, kThrottlePedalTooLow, kTransferDataSuspended, kTransmissionRangeNotInGear, kTransmissionRangeNotInNeutral, kUploadDownloadNotAccepted, kVehicleSpeedTooHigh, kVehicleSpeedTooLow, kVoltageTooHigh, kVoltageTooLow, kWrongBlockSequenceCounter]  # This error set includes all NegativeResponseCodes defined in UDS.
  ap application error set UDSNegativeResponseCodeValidation: ap-application-error=[kBrakeSwitchNotClosed, kBusyRepeatRequest, kConditionsNotCorrect, kEngineIsNotRunning, kEngineIsRunning, kEngineRunTimeTooLow, kExceedNumberOfAttempts, kFailurePreventsExecutionOfRequestedAction, kGeneralReject, kGeneralProgrammingFailure, kIncorrectMessageLengthOrInvalidFormat, kInvalidKey, kNoProcessingNoResponse, kNoResponseFromSubnetComponent, kResponseTooLong, kRequestOutOfRange, kRequestSequenceError, kRequiredTimeDelayNotExpired, kRpmTooHigh, kRpmTooLow, kSecurityAccessDenied, kServiceNotSupported, kServiceNotSupportedInActiveSession, kShifterLeverNotInPark, kSubfunctionNotSupported, kSubFunctionNotSupportedInActiveSession, kTemperatureTooHigh, kTemperatureTooLow, kTorqueConverterClutchLocked, kThrottlePedalTooHigh, kThrottlePedalTooLow, kTransferDataSuspended, kTransmissionRangeNotInGear, kTransmissionRangeNotInNeutral, kUploadDownloadNotAccepted, kVehicleSpeedTooHigh, kVehicleSpeedTooLow, kVoltageTooHigh, kVoltageTooLow, kWrongBlockSequenceCounter]  # This error set includes all NegativeResponseCodes defined in UDS + the possbility to reject the request message without any response message.
package /AUTOSAR/DataConstrs_Blueprint
  range ClearFailedReasonType: raw 0x00..0x03
package /AUTOSAR/CompuMethods_Blueprint
  compu method MetaInfoKeyTypeEnum: 0x00=kSA (UDS Source Address from which the diagnostic request has been sent. The value in the MetaInf Map for this key, will be a stringified form of UDS source address in hex. For example tester SA of decimal 240 will have the stringified value “F0”), 0x01=kTA (UDS Target Address to which the diagnostic request has been sent. The value in the MetaInf Map for this key, will be a stringified form of UDS source address in hex. For example TA of decimal 59 will have the stringified value “3B”), 0x02=kRequestHandle (Key for the RequestHandle parameter of the current service request. The value in the MetaInf Map for this key, will be the stringified decimal representation of the RequestHandle.), 0x03=kRequestType (Indicator whether request is functional or physical addressed. The value in the MetaInf Map for this key, will be either “PHYS” or “FUNC”), 0x06=kSuppPosResponse (Key for the flag, whether positive response shall be suppressed for current request. The value in the MetaInf Map for this key, will be the either “TRUE” or “FLASE”), 0x07=kProtocolId (The identifier which can be used to call FindService(PROTOCOL_ID) to find the DiagnosticConversation ServiceInstance.), 0x08=kDoIPLocalIP (Key for the local IP address on which the current request gets received in case of DoIP is used as UDS transport layer (this might be of interest in case the ECU is multi-homed and could receive diagnostic requests via DoIP on different interfaces). The value in the MetaInf Map for this key, will be either a string in IPv4 address notation (decimal representation of address parts separated with “.”) or a string in IPv6 notation (hexadecimal representation of address parts separated with “:” according to section 2.2 of RFC 4291), 0x09=kDoIPLocalPort (Key for the local port number on which the current request gets received in case of DoIP is used as UDS transport layer. The value in the MetaInf Map for this key, will be the stringified decimal representation of the port number.), 0x0A=kDoIPRemoteIP (Key for the remote IP address on which the current request gets received in case of DoIP is used as UDS transport layer. The value in the MetaInf Map for this key, will be either a string in IPv4 address notation (decimal representation of address parts separated with “.”) or a string in IPv6 notation (hexadecimal representation of address parts separated with “:” according to section 2.2 of RFC 4291)), 0x0B=kDoIPRemotePort (Key for the remote port number on which the current request gets received in case of DoIP is used as UDS transport layer. The value in the MetaInf Map for this key, will be the stringified decimal representation of the port number.)
package /AUTOSAR/StringType
  std cpp implementation data type string: category=STRING, type-emitter=string
